# MSP430F5529 register map
Vendor: msp430gen; File version: VERGEN_IDEMPOTENT_OUTPUT
Registers are 8-bit, read-write, reset 0x0 unless marked. A register's access mark holds for its fields unless they carry their own. Offsets are from the block's base; [hi:lo] are bit positions; {n}, {i} and the like mark numbered series; 'fields as' and 'values as' point back to an identical list.

## USB_OPERATION
Base 0x00001C00
0x00 USBSTABUFF — Start of buffer space
0x76F USBTOPBUFF — Top of buffer space
0x770 USBOEP0BUF — Output endpoint_0 buffer
0x778 USBIEP0BUF — Input endpoint_0 buffer
0x780 USBSUBLK — Setup Packet Block
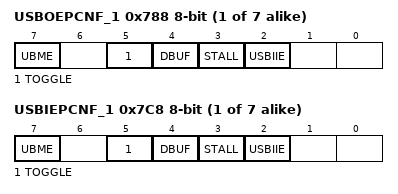
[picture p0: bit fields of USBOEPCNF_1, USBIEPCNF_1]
{0x780+8i} USBOEPCNF_{i} (i=1..7) — Output Endpoint_{i}: Configuration
  [7] UBME — USB - UBM In-Endpoint Enable
  [5] TOGGLE — USB - Toggle Bit
  [4] DBUF — USB - Double Buffer Enable
  [3] STALL — USB - Stall Condition
  [2] USBIIE — USB - Transaction Interrupt indication enable
{0x781+8i} USBOEPBBAX_{i} (i=1..7) — Output Endpoint_{i}: X-buffer base addr.
{0x782+8i} USBOEPBCTX_{i} (i=1..7) — Output Endpoint_{i}: X-byte count
{0x785+8i} USBOEPBBAY_{i} (i=1..7) — Output Endpoint_{i}: Y-buffer base addr.
{0x786+8i} USBOEPBCTY_{i} (i=1..7) — Output Endpoint_{i}: Y-byte count
{0x787+8i} USBOEPSIZXY_{i} (i=1..7) — Output Endpoint_{i}: X/Y-buffer size
{0x7C0+8i} USBIEPCNF_{i} (i=1..7) — Input Endpoint_{i}: Configuration
  fields as USBOEPCNF_1
{0x7C1+8i} USBIEPBBAX_{i} (i=1..7) — Input Endpoint_{i}: X-buffer base addr.
{0x7C2+8i} USBIEPBCTX_{i} (i=1..7) — Input Endpoint_{i}: X-byte count
{0x7C5+8i} USBIEPBBAY_{i} (i=1..7) — Input Endpoint_{i}: Y-buffer base addr.
{0x7C6+8i} USBIEPBCTY_{i} (i=1..7) — Input Endpoint_{i}: Y-byte count
{0x7C7+8i} USBIEPSIZXY_{i} (i=1..7) — Input Endpoint_{i}: X/Y-buffer size

## SFR — SFR Special Function Registers
Base 0x00000100
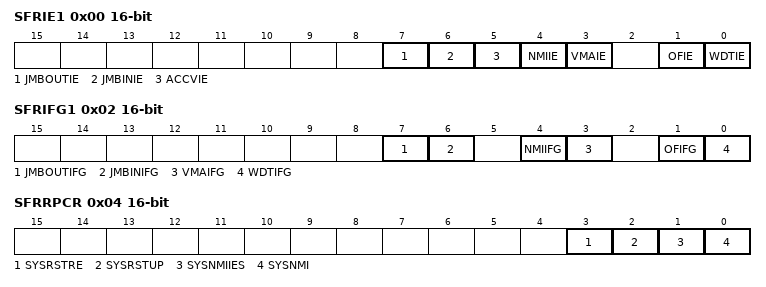
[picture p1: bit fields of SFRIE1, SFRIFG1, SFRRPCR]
0x00 SFRIE1 16-bit — Interrupt Enable 1
  [7] JMBOUTIE — JTAG Mail Box output Interrupt Enable
  [6] JMBINIE — JTAG Mail Box input Interrupt Enable
  [5] ACCVIE — Flash Access Violation Interrupt Enable
  [4] NMIIE — NMI Interrupt Enable
  [3] VMAIE — Vacant Memory Interrupt Enable
  [1] OFIE — Osc Fault Enable
  [0] WDTIE — WDT Interrupt Enable
0x02 SFRIFG1 16-bit — Interrupt Flag 1
  [7] JMBOUTIFG — JTAG Mail Box output Interrupt Flag
  [6] JMBINIFG — JTAG Mail Box input Interrupt Flag
  [4] NMIIFG — NMI Interrupt Flag
  [3] VMAIFG — Vacant Memory Interrupt Flag
  [1] OFIFG — Osc Fault Flag
  [0] WDTIFG — WDT Interrupt Flag
0x04 SFRRPCR 16-bit — RESET Pin Control Register
  [3] SYSRSTRE — RESET Pin Resistor enable
  [2] SYSRSTUP — RESET Pin pull down/up select
  [1] SYSNMIIES — NMI edge select
  [0] SYSNMI — NMI select

## FLASH
Base 0x00000140
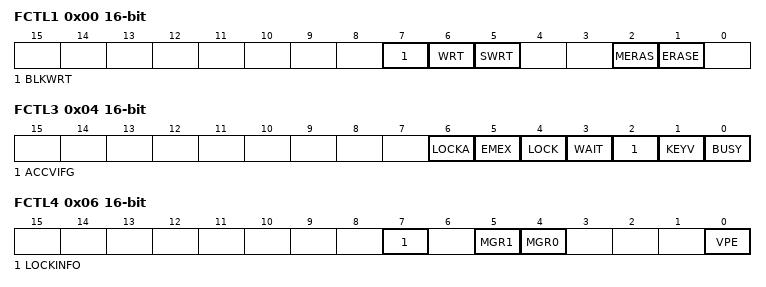
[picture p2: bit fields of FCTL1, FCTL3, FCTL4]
0x00 FCTL1 16-bit — FLASH Control 1
  [7] BLKWRT — Enable bit for Flash segment write
  [6] WRT — Enable bit for Flash write
  [5] SWRT — Smart Write enable
  [2] MERAS — Enable bit for Flash mass erase
  [1] ERASE — Enable bit for Flash segment erase
0x04 FCTL3 16-bit — FLASH Control 3
  [6] LOCKA — Segment A Lock bit: read = 1 - Segment is locked (read only)
  [5] EMEX — Flash Emergency Exit
  [4] LOCK — Lock bit: 1 - Flash is locked (read only)
  [3] WAIT — Wait flag for segment write
  [2] ACCVIFG — Flash Access violation flag
  [1] KEYV — Flash Key violation flag
  [0] BUSY — Flash busy: 1
0x06 FCTL4 16-bit — FLASH Control 4
  [7] LOCKINFO — Lock INFO Memory bit: read = 1 - Segment is locked (read only)
  [5] MGR1 — Marginal read 1 mode.
  [4] MGR0 — Marginal read 0 mode.
  [0] VPE — Voltage Changed during Program Error Flag

## CRC16
Base 0x00000150
0x00 CRCDI 16-bit — CRC Data In Register
0x02 CRCDIRB 16-bit — CRC data in reverse byte Register
0x04 CRCINIRES 16-bit — CRC Initialisation Register and Result Register
0x06 CRCRESR 16-bit — CRC reverse result Register

## RC — RC RAM Control Module
Base 0x00000158
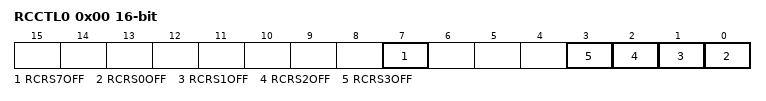
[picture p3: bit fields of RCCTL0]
0x00 RCCTL0 16-bit — Ram Controller Control Register
  [7] RCRS7OFF — RAM Controller RAM Sector 7 (USB) Off
  [n] RCRS{n}OFF (n=0..3) — RAM Controller RAM Sector {n} Off

## WATCHDOG_TIMER
Base 0x0000015C
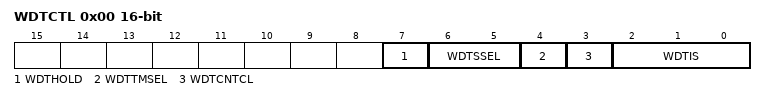
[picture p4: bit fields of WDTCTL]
0x00 WDTCTL 16-bit — Watchdog Timer Control
  [7] WDTHOLD — WDT - Timer hold
  [6:5] WDTSSEL — WDT - Timer Clock Source Select 0
    0=WDT - Timer Clock Source Select: SMCLK; 1=WDT - Timer Clock Source Select: ACLK; 2=WDT - Timer Clock Source Select: VLO_CLK; 3=WDT - Timer Clock Source Select: reserved
  [4] WDTTMSEL — WDT - Timer Mode Select
  [3] WDTCNTCL — WDT - Timer Clear
  [2:0] WDTIS — WDT - Timer Interval Select 0
    0=WDT - Timer Interval Select: /2G; 1=WDT - Timer Interval Select: /128M; 2=WDT - Timer Interval Select: /8192k; 3=WDT - Timer Interval Select: /512k; 4=WDT - Timer Interval Select: /32k; 5=WDT - Timer Interval Select: /8192; 6=WDT - Timer Interval Select: /512; 7=WDT - Timer Interval Select: /64
